# NUC100CN_v1 register map
File version: 1.0
Registers are 32-bit, read-write, reset 0x0 unless marked. A register's access mark holds for its fields unless they carry their own. Offsets are from the block's base; [hi:lo] are bit positions; 'fields as' and 'values as' point back to an identical list.

## UART0 — UART Register Map
Base 0x40050000
0x00 UA_RBR ro reset not defined — UART Receive Buffer Register
  [7:0] RBR — Receive Buffer Register (Read Only). By reading this register, the UART will return an 8-bit data received from RX pin (LSB first).
0x00 UA_THR wo reset not defined (alternate view of UA_RBR) — UART Transmit Holding Register
  [7:0] THR — Transmit Holding Register. By writing to this register, the UART will send out an 8-bit data through the TX pin (LSB first).
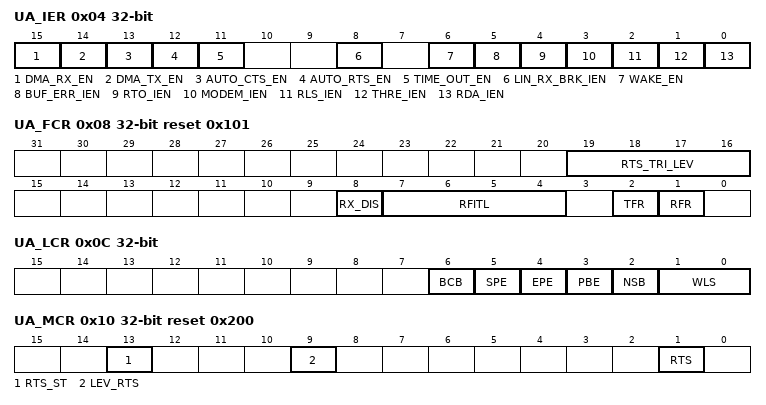
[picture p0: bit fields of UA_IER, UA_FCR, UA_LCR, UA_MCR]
0x04 UA_IER — UART Interrupt Enable Register
  [15] DMA_RX_EN — RX DMA Enable (Not Available in UART2 Channel). This bit can enable or disable RX DMA service.
    0=RX DMA Disabled; 1=RX DMA Enabled
  [14] DMA_TX_EN — TX DMA Enable (Not Available in UART2 Channel). This bit can enable or disable TX DMA service.
    0=TX DMA Disabled; 1=TX DMA Enabled
  [13] AUTO_CTS_EN — CTS Auto Flow Control Enable (Not Available in UART2 Channel). When CTS auto-flow is enabled, the UART will send data to external device when CTS input assert (UART will not send data to device until CTS is asserted).
    0=CTS auto flow control Disabled; 1=CTS auto flow control Enabled
  [12] AUTO_RTS_EN — RTS Auto Flow Control Enable (Not Available in UART2 Channel). When RTS auto-flow is enabled, if the number of bytes in the RX FIFO equals the UA_FCR [RTS_TRI_LEV], the UART will de-assert RTS signal.
    0=RTS auto flow control Disabled; 1=RTS auto flow control Enabled
  [11] TIME_OUT_EN — Time Out Counter Enable
    0=Time-out counter Disabled; 1=Time-out counter Enabled
  [8] LIN_RX_BRK_IEN — LIN RX Break Field Detected Interrupt Enable. Note: This field is used for LIN function mode.
    0=Lin bus RX break filed interrupt Masked off; 1=Lin bus RX break filed interrupt Enabled
  [6] WAKE_EN — UART Wake-up Function Enable (Not Available in UART2 Channel)
    0=UART wake-up function Disabled; 1=UART wake-up function Enabled. When the chip is in Power-down mode, an external CTS change will wake-up chip from Power-down mode
  [5] BUF_ERR_IEN — Buffer Error Interrupt Enable
    0=INT_BUF_ERR Masked off; 1=INT_BUF_ERR Enabled
  [4] RTO_IEN — RX Time Out Interrupt Enable
    0=INT_TOUT Masked off; 1=INT_TOUT Enabled
  [3] MODEM_IEN — Modem Status Interrupt Enable (Not Available in UART2 Channel)
    0=INT_MODEM Masked off; 1=INT_MODEM Enabled
  [2] RLS_IEN — Receive Line Status Interrupt Enable
    0=INT_RLS Masked off; 1=INT_RLS Enabled
  [1] THRE_IEN — Transmit Holding Register Empty Interrupt Enable
    0=INT_THRE Masked off; 1=INT_THRE Enabled
  [0] RDA_IEN — Receive Data Available Interrupt Enable.
    0=INT_RDA Masked off; 1=INT_RDA Enabled
0x08 UA_FCR reset 0x101 — UART FIFO Control Register
  [19:16] RTS_TRI_LEV — RTS Trigger Level for Auto-Flow Control Use (Not Available in UART2 Channel)
  [8] RX_DIS — Receiver Disable register. The receiver is disabled or not (set 1 to disable receiver). Note: This field is used for RS-485 Normal Multi-drop mode. It should be programmed before UA_ALT_CSR [RS-485_NMM] is programmed.
    0=Receiver Enabled; 1=Receiver Disabled
  [7:4] RFITL — RX FIFO Interrupt (INT_RDA) Trigger Level
  [2] TFR — TX Field Software Reset. When TX_RST is set, all the byte in the transmit FIFO and TX internal state machine are cleared. Note: This bit will auto clear needs at least 3 UART engine clock cycles.
    0=Writing 0 to this bit has no effect; 1=Writing 1 to this bit will reset the TX internal state machine and pointers
  [1] RFR — RX Field Software Reset. When RX_RST is set, all the byte in the receiver FIFO and RX internal state machine are cleared. Note: This bit will auto clear needs at least 3 UART engine clock cycles.
    0=Writing 0 to this bit has no effect; 1=Writing 1 to this bit will reset the RX internal state machine and pointers
0x0C UA_LCR — UART Line Control Register
  [6] BCB — Break Control Bit. When this bit is set to logic 1, the serial data output (TX) is forced to the Spacing State (logic 0). This bit acts only on TX and has no effect on the transmitter logic.
  [5] SPE — Stick Parity Enable
    0=Stick parity Disabled; 1=If bit 3 and 4 are logic 1, the parity bit is transmitted and checked as logic 0. If bit 3 is 1 and bit 4 is 0 then the parity bit is transmitted and checked as 1
  [4] EPE — Even Parity Enable. This bit has effect only when bit 3 (parity bit enable) is set.
    0=Odd number of logic 1's is transmitted and checked in each word; 1=Even number of logic 1's is transmitted and checked in each word
  [3] PBE — Parity Bit Enable
    0=No parity bit; 1=Parity bit is generated on each outgoing character and is checked on each incoming data
  [2] NSB — Number of "STOP bit"
    0=1 STOP bit; 1=2 STOP bits (1.5 STOP bits if WLS[1:0]=00)
  [1:0] WLS — Word Length Select
0x10 UA_MCR reset 0x200 — UART Modem Control Register. UART2: Reserved
  [13] RTS_ST ro — RTS Pin State (Read Only) (Not Available in UART2 Channel). This bit is the output pin status of RTS.
  [9] LEV_RTS — RTS Trigger Level (Not Available in UART2 Channel). This bit can change the RTS trigger level.
    0=low level triggered; 1=high level triggered
  [1] RTS — RTS (Request-To-Send) Signal (Not Available in UART2 Channel)
    0=Drive RTS pin to logic 1 (If the LEV_RTS set to low level triggered). Drive RTS pin to logic 0 (If the LEV_RTS set to high level triggered); 1=Drive RTS pin to logic 0 (If the LEV_RTS set to low level triggered). Drive RTS pin to logic 1 (If the LEV_RTS set to high level triggered)
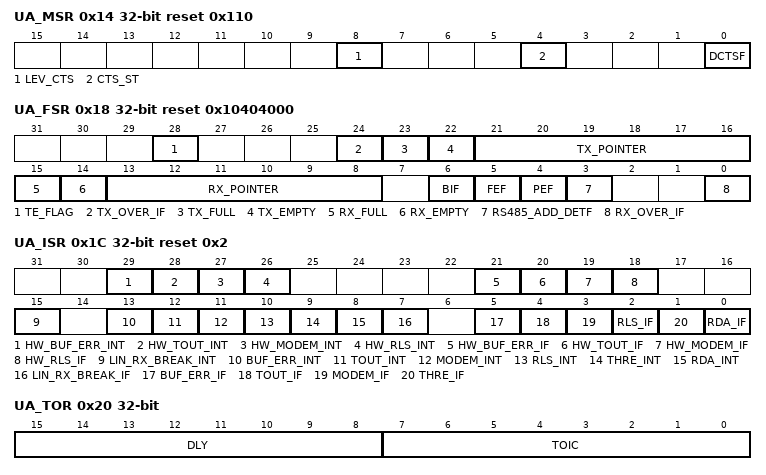
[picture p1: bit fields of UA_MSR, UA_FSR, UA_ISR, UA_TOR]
0x14 UA_MSR reset 0x110 — UART Modem Status Register. UART2: Reserved
  [8] LEV_CTS — CTS Trigger Level (Not Available in UART2 Channel). This bit can change the CTS trigger level.
    0=low level triggered; 1=high level triggered
  [4] CTS_ST ro — CTS Pin Status (Read Only) (Not Available in UART2 Channel). This bit is the pin status of CTS.
  [0] DCTSF ro — Detect CTS State Change Flag (Read Only) (Not Available in UART2 Channel). This bit is set whenever CTS input has change state, and it will generate Modem interrupt to CPU when UA_IER [MODEM_IEN] is set to 1. Software can write 1 to clear this bit to 0
0x18 UA_FSR reset 0x10404000 — UART FIFO Status Register
  [28] TE_FLAG ro — Transmitter Empty Flag (Read Only). Bit is set by hardware when TX FIFO (UA_THR) is empty and the STOP bit of the last byte has been transmitted. Bit is cleared automatically when TX FIFO is not empty or the last byte transmission has not completed.
  [24] TX_OVER_IF ro — TX Overflow Error Interrupt Flag (Read Only). If TX FIFO (UA_THR) is full, an additional write to UA_THR will cause this bit to logic 1. Note: This bit is read only, but can be cleared by writing '1' to it.
  [23] TX_FULL ro — Transmitter FIFO Full (Read Only). This bit indicates TX FIFO full or not. This bit is set when the number of usage in TX FIFO Buffer is equal to 64/16/16(UART0/UART1/UART2), otherwise is cleared by hardware.
  [22] TX_EMPTY ro — Transmitter FIFO Empty (Read Only). This bit indicates TX FIFO empty or not. When the last byte of TX FIFO has been transferred to Transmitter Shift Register, hardware sets this bit high. It will be cleared when writing data into THR (TX FIFO not empty).
  [21:16] TX_POINTER ro — TX FIFO Pointer (Read Only). This field indicates the TX FIFO Buffer Pointer. When CPU writes one byte into UA_THR, TX_POINTER increases one. When one byte of TX FIFO is transferred to Transmitter Shift Register, TX_POINTER decreases one. The Maximum value shows in TX_POINTER is 63/15/15 (UART0/UART1/UART2). When the using level of TX FIFO Buffer equal to 64/16/16, the TX_FULL bit is set to 1 and TX_POINTER will show 0. As one byte of TX FIFO is transferred to Transmitter Shift Register, the TX_FULL bit is clear to 0 and TX_POINTER will show 63/15/15 (UART0/UART1/UART2).
  [15] RX_FULL ro — Receiver FIFO Full (Read Only). This bit initiates RX FIFO full or not. This bit is set when the number of usage in RX FIFO Buffer is equal to 64/16/16(UART0/UART1/UART2); otherwise, it is cleared by hardware.
  [14] RX_EMPTY ro — Receiver FIFO Empty (Read Only). This bit initiate RX FIFO empty or not. When the last byte of RX FIFO has been read by CPU, hardware sets this bit high. It will be cleared when UART receives any new data.
  [13:8] RX_POINTER ro — RX FIFO Pointer (Read Only). This field indicates the RX FIFO Buffer Pointer. When UART receives one byte from external device, RX_POINTER increases one. When one byte of RX FIFO is read by CPU, RX_POINTER decreases one. The Maximum value shows in RX_POINTER is 63/15/15 (UART0/UART1/UART2). When the using level of RX FIFO Buffer equal to 64/16/16, the RX_FULL bit is set to 1 and RX_POINTER will show 0. As one byte of RX FIFO is read by CPU, the RX_FULL bit is clear to 0 and RX_POINTER will show 63/15/15 (UART0/UART1/UART2).
  [6] BIF ro — Break Interrupt Flag (Read Only). This bit is set to a logic 1 whenever the received data input(RX) is held in the "spacing state" (logic 0) for longer than a full word transmission time (that is, the total time of "start bit" + data bits + parity + stop bits) and is reset whenever the CPU writes 1 to this bit. Note: This bit is read only, but can be cleared by writing '1' to it.
  [5] FEF ro — Framing Error Flag (Read Only). This bit is set to logic 1 whenever the received character does not have a valid "stop bit" (that is, the stop bit following the last data bit or parity bit is detected as a logic 0), and is reset whenever the CPU writes 1 to this bit. Note: This bit is read only, but can be cleared by writing '1' to it.
  [4] PEF ro — Parity Error Flag (Read Only). This bit is set to logic 1 whenever the received character does not have a valid "parity bit", and is reset whenever the CPU writes 1 to this bit. Note: This bit is read only, but can be cleared by writing '1' to it.
  [3] RS485_ADD_DETF ro — RS-485 Address Byte Detection Flag (Read Only). Note: This field is used for RS-485 function mode. Note: This bit is read only, but can be cleared by writing '1' to it.
  [0] RX_OVER_IF ro — RX Overflow Error IF (Read Only). This bit is set when RX FIFO overflow. If the number of bytes of received data is greater than RX_FIFO (UA_RBR) size, 64/16 bytes of UART0/UART1, this bit will be set. Note: This bit is read only, but can be cleared by writing '1' to it.
0x1C UA_ISR reset 0x2 — UART Interrupt Status Register
  [29] HW_BUF_ERR_INT ro — In DMA Mode, Buffer Error Interrupt Indicator (Read Only). This bit is set if BUF_ERR_IEN and HW_BUF_ERR_IF are both set to 1.
    0=No buffer error interrupt is generated in DMA mode; 1=The buffer error interrupt is generated in DMA mode
  [28] HW_TOUT_INT ro — In DMA Mode, Time Out Interrupt Indicator (Read Only). This bit is set if TOUT_IEN and HW_TOUT_IF are both set to 1.
    0=No Tout interrupt is generated in DMA mode; 1=Tout interrupt is generated in DMA mode
  [27] HW_MODEM_INT ro — In DMA Mode, MODEM Status Interrupt Indicator (Read Only) (Not Available in UART2 Channel). This bit is set if MODEM_IEN and HW_MODEM_IF are both set to 1.
    0=No Modem interrupt is generated in DMA mode; 1=Modem interrupt is generated in DMA mode
  [26] HW_RLS_INT ro — In DMA Mode, Receive Line Status Interrupt Indicator (Read Only). This bit is set if RLS_IEN and HW_RLS_IF are both set to 1.
    0=No RLS interrupt is generated in DMA mode; 1=RLS interrupt is generated in DMA mode
  [21] HW_BUF_ERR_IF ro — In DMA Mode, Buffer Error Interrupt Flag (Read Only). This bit is set when the TX or RX FIFO overflows (TX_OVER_IF or RX_OVER_IF is set). When BUF_ERR_IF is set, the transfer maybe is not correct. If UA_IER [BUF_ERR_IEN] is enabled, the buffer error interrupt will be generated. Note: This bit is cleared when both TX_OVER_IF and RX_OVER_IF are cleared.
  [20] HW_TOUT_IF ro — In DMA Mode, Time Out Interrupt Flag (Read Only). This bit is set when the RX FIFO is not empty and no activities occurred in the RX FIFO and the time out counter equal to TOIC. If UA_IER [TOUT_IEN] is enabled, the Tout interrupt will be generated. Note: This bit is read only and user can read UA_RBR (RX is in active) to clear it.
  [19] HW_MODEM_IF ro — In DMA Mode, MODEM Interrupt Flag (Read Only) (Not Available in UART2 Channel). Note: This bit is read only and reset to 0 when bit DCTSF is cleared by a write 1 on DCTSF.
  [18] HW_RLS_IF ro — In DMA Mode, Receive Line Status Flag (Read Only). This bit is set when the RX receive data have parity error, framing error or break error (at least one of 3 bits, BIF, FEF and PEF, is set). If UA_IER [RLS_IEN] is enabled, the RLS interrupt will be generated. Note: This bit is read only and reset to 0 when all bits of BIF, FEF and PEF are cleared.
  [15] LIN_RX_BREAK_INT ro — LIN Bus RX Break Field Detected Interrupt Indicator (Read Only). This bit is set if LIN_RX_BRK_IEN and LIN_RX_BREAK_IF are both set to 1.
    0=No LIN RX Break interrupt is generated; 1=LIN RX Break interrupt is generated
  [13] BUF_ERR_INT ro — Buffer Error Interrupt Indicator (Read Only). This bit is set if BUF_ERR_IEN and BUF_ERR_IF are both set to 1.
    0=No buffer error interrupt is generated; 1=The buffer error interrupt is generated
  [12] TOUT_INT ro — Time Out Interrupt Indicator (Read Only). This bit is set if TOUT_IEN and TOUT_IF are both set to 1.
    0=No Tout interrupt is generated; 1=Tout interrupt is generated
  [11] MODEM_INT ro — MODEM Status Interrupt Indicator (Read Only) (Not Available in UART2 Channel). This bit is set if MODEM_IEN and MODEM_IF are both set to 1.
    0=No Modem interrupt is generated; 1=Modem interrupt is generated
  [10] RLS_INT ro — Receive Line Status Interrupt Indicator (Read Only). This bit is set if RLS_IEN and RLS_IF are both set to 1.
    0=No RLS interrupt is generated; 1=RLS interrupt is generated
  [9] THRE_INT ro — Transmit Holding Register Empty Interrupt Indicator (Read Only). This bit is set if THRE_IEN and THRE_IF are both set to 1.
    0=No THRE interrupt is generated; 1=THRE interrupt is generated
  [8] RDA_INT ro — Receive Data Available Interrupt Indicator (Read Only). This bit is set if RDA_IEN and RDA_IF are both set to 1.
    0=No RDA interrupt is generated; 1=RDA interrupt is generated
  [7] LIN_RX_BREAK_IF ro — LIN Bus RX Break Field Detected Flag (Read Only). This bit is set when RX received LIN Break Field. If UA_IER [LIN_RX_BRK_IEN] is enabled the LIN RX Break interrupt will be generated. Note: This bit is read only, but can be cleared by writing '1' to it.
  [5] BUF_ERR_IF ro — Buffer Error Interrupt Flag (Read Only). This bit is set when the TX or RX FIFO overflows or Break Interrupt Flag or Parity Error Flag or Frame Error Flag (TX_OVER_IF or RX_OVER_IF or BIF or PEF or FEF) is set. When BUF_ERR_IF is set, the transfer is not correct. If UA_IER [BUF_ERR_IEN] is enabled, the buffer error interrupt will be generated.
  [4] TOUT_IF ro — Time Out Interrupt Flag (Read Only). This bit is set when the RX FIFO is not empty and no activities occurred in the RX FIFO and the time out counter equal to TOIC. If UA_IER [TOUT_IEN] is enabled, the Tout interrupt will be generated. Note: This bit is read only and user can read UA_RBR (RX is in active) to clear it.
  [3] MODEM_IF ro — MODEM Interrupt Flag (Read Only) (Not Available in UART2 Channel). Note: This bit is read only and reset to 0 when bit DCTSF is cleared by a write 1 on DCTSF.
  [2] RLS_IF ro — Receive Line Interrupt Flag (Read Only). This bit is set when the RX receive data have parity error, framing error or break error (at least one of 3 bits, BIF, FEF and PEF, is set). If UA_IER [RLS_IEN] is enabled, the RLS interrupt will be generated. Note: This bit is read only and reset to 0 when all bits of BIF, FEF and PEF are cleared.
  [1] THRE_IF ro — Transmit Holding Register Empty Interrupt Flag (Read Only). This bit is set when the last data of TX FIFO is transferred to Transmitter Shift Register. If UA_IER [THRE_IEN] is enabled, the THRE interrupt will be generated. Note: This bit is read only and it will be cleared when writing data into THR (TX FIFO not empty).
  [0] RDA_IF ro — Receive Data Available Interrupt Flag (Read Only). When the number of bytes in the RX FIFO equals the RFITL then the RDA_IF will be set. If UA_IER [RDA_IEN] is enabled, the RDA interrupt will be generated. Note: This bit is read only and it will be cleared when the number of unread bytes of RX FIFO drops below the threshold level (RFITL).
0x20 UA_TOR — UART Time Out Register
  [15:8] DLY — TX Delay Time Value. This field is use to programming the transfer delay time between the last stop bit and next start bit.
  [7:0] TOIC — Time Out Interrupt Comparator
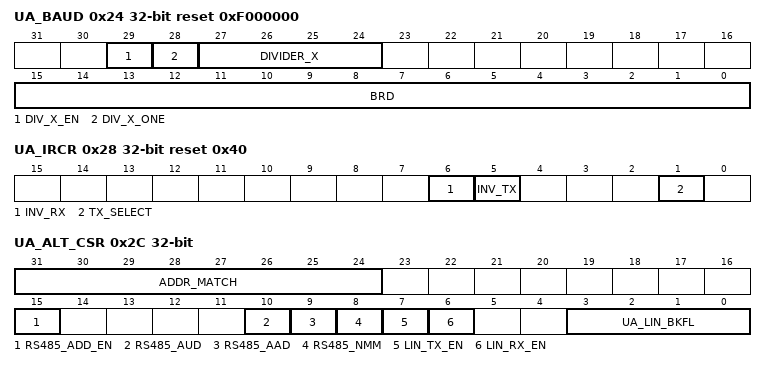
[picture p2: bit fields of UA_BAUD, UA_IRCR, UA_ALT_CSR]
0x24 UA_BAUD reset 0xF000000 — UART Baud Rate Divisor Register
  [29] DIV_X_EN — Divider X Enable. Refer to the table below for more information. Note: In IrDA mode, this bit must be disabled.
    0=Divider X Disabled (the equation of M = 16); 1=Divider X Enabled (the equation of M = X+1, but DIVIDER_X [27:24] must = 8)
  [28] DIV_X_ONE — Divider X equal 1. Refer to the Table 513 below for more information.
    0=Divider M = X (the equation of M = X+1, but DIVIDER_X[27:24] must = 8); 1=Divider M = 1 (the equation of M = 1, but BRD [15:0] must = 3)
  [27:24] DIVIDER_X
  [15:0] BRD — Baud Rate Divider. The field indicates the baud rate divider.
0x28 UA_IRCR reset 0x40 — UART IrDA Control Register
  [6] INV_RX
    0=No inversion; 1=Inverse RX input signal
  [5] INV_TX
    0=No inversion; 1=Inverse TX output signal
  [1] TX_SELECT
    0=Enable IrDA receiver; 1=Enable IrDA transmitter
0x2C UA_ALT_CSR — UART Alternate Control/Status Register
  [31:24] ADDR_MATCH — Address match value register. This field contains the RS-485 address match values. Note: This field is used for RS-485 auto address detection mode.
  [15] RS485_ADD_EN — RS-485 Address Detection Enable. This bit is use to enable RS-485 address detection mode. Note: This field is used for RS-485 any operation mode.
    0=Address detection mode Disabled; 1=Address detection mode Enabled
  [10] RS485_AUD — RS-485 Auto Direction Mode (AUD). Note: It can be active with RS-485_AAD or RS-485_NMM operation mode.
    0=RS-485 Auto Direction Operation Mode (AUO) Disabled; 1=RS-485 Auto Direction Operation Mode (AUO) Enabled
  [9] RS485_AAD — RS-485 Auto Address Detection Operation Mode (AAD). Note: It cannot be active in RS-485_NMM operation mode.
    0=RS-485 Auto Address Detection Operation Mode (AAD) Disabled; 1=RS-485 Auto Address Detection Operation Mode (AAD) Enabled
  [8] RS485_NMM — RS-485 Normal Multi-drop Operation Mode (NMM). Note: It cannot be active in RS-485_AAD operation mode.
    0=RS-485 Normal Multi-drop Operation mode (NMM) Disabled; 1=RS-485 Normal Multi-drop Operation Mode (NMM) Enabled
  [7] LIN_TX_EN — LIN TX Break Mode Enable. Note: When TX break field transfer operation is finished, this bit will be cleared automatically.
    0=LIN TX Break mode. Disabled; 1=LIN TX Break mode. Enabled
  [6] LIN_RX_EN — LIN RX Enable
    0=LIN RX mode Disabled; 1=LIN RX mode Enabled
  [3:0] UA_LIN_BKFL — UART LIN Break Field Length. This field indicates a 4-bit LIN TX break field count. Note: This break field length is UA_LIN_BKFL + 2
0x30 UA_FUN_SEL — UART Function Select Register
  [1:0] FUN_SEL — Function Select Enable
    0=UART function; 1=LIN function Enabled; 2=IrDA function Enabled; 3=RS-485 function Enabled

## UART1 — UART Register Map
Base 0x40150000
Registers as UART0; these are added or differ:
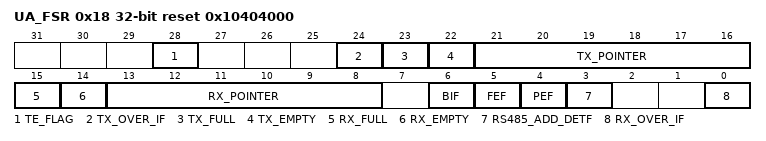
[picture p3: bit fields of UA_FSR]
0x18 UA_FSR reset 0x10404000 — UART FIFO Status Register
  fields as UART0.UA_FSR
